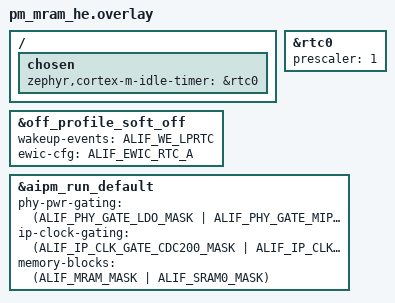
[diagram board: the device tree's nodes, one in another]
/* Copyright (C) 2026 Alif Semiconductor - All Rights Reserved.
 * Use, distribution and modification of this code is permitted under the
 * terms stated in the Alif Semiconductor Software License Agreement
 *
 * You should have received a copy of the Alif Semiconductor Software
 * License Agreement with this file. If not, please write to:
 * contact@alifsemi.com, or visit: https://alifsemi.com/license
 *
 */

/*
 * PM SOFT_OFF overlay for HE core booting from MRAM.
 * Uses RTC as wakeup source and idle timer.
 */

#include "pm_mram_common.overlay"

&rtc0 {
	prescaler = <1>;
	status = "okay";
};

&off_profile_soft_off {
	wakeup-events = <ALIF_WE_LPRTC>;
	ewic-cfg      = <ALIF_EWIC_RTC_A>;
};

/ {
	chosen {
		zephyr,cortex-m-idle-timer = &rtc0;
	};
};

&aipm_run_default {
	phy-pwr-gating = <(ALIF_PHY_GATE_LDO_MASK |
			ALIF_PHY_GATE_MIPI_TX_DPHY_MASK |
			ALIF_PHY_GATE_MIPI_RX_DPHY_MASK |
			ALIF_PHY_GATE_MIPI_PLL_DPHY_MASK)>;
	ip-clock-gating = <(ALIF_IP_CLK_GATE_CDC200_MASK |
			ALIF_IP_CLK_GATE_MIPI_DSI_MASK |
			ALIF_IP_CLK_GATE_GPU_MASK)>;
	memory-blocks   = <(ALIF_MRAM_MASK | ALIF_SRAM0_MASK)>;
};
